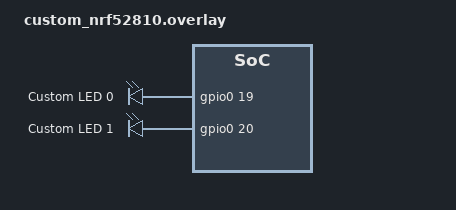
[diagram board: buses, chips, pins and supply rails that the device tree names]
/ {
	aliases {
		led0 = &custom_led0;
		led1 = &custom_led1;
	};

	leds {
		compatible = "gpio-leds";

		custom_led0: led_0 {
			gpios = <&gpio0 19 GPIO_ACTIVE_HIGH>;
			label = "Custom LED 0";
		};

		custom_led1: led_1 {
			gpios = <&gpio0 20 GPIO_ACTIVE_HIGH>;
			label = "Custom LED 1";
		};
	};
};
